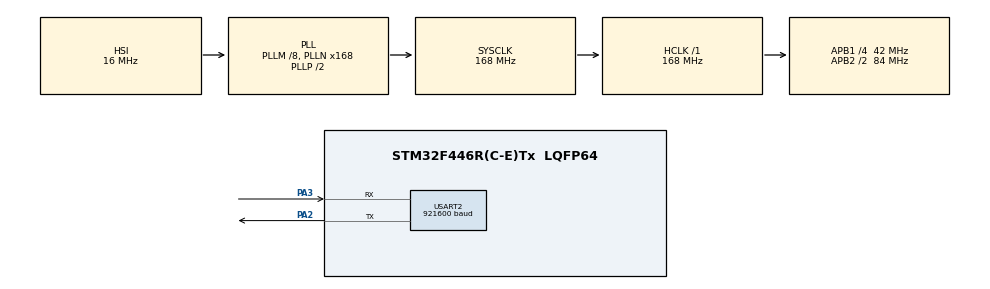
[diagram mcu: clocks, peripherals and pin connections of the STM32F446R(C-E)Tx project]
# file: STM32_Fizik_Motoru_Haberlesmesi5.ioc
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Dma.Request0=USART2_RX
Dma.USART2_RX.0.Direction=DMA_PERIPH_TO_MEMORY
Dma.USART2_RX.0.FIFOMode=DMA_FIFOMODE_DISABLE
Dma.USART2_RX.0.Instance=DMA1_Stream5
Dma.USART2_RX.0.MemDataAlignment=DMA_MDATAALIGN_BYTE
Dma.USART2_RX.0.MemInc=DMA_MINC_ENABLE
Dma.USART2_RX.0.Mode=DMA_NORMAL
Dma.USART2_RX.0.PeriphDataAlignment=DMA_PDATAALIGN_BYTE
Dma.USART2_RX.0.PeriphInc=DMA_PINC_DISABLE
Dma.USART2_RX.0.Priority=DMA_PRIORITY_HIGH
Mcu.Family=STM32F4
Mcu.Name=STM32F446R(C-E)Tx
Mcu.Package=LQFP64
NVIC.DMA1_Stream5_IRQn=true\:0\:0\:false\:false\:true\:false\:true\:true
NVIC.PriorityGroup=NVIC_PRIORITYGROUP_4
NVIC.TIM3_IRQn=true\:0\:0\:false\:false\:true\:true\:true\:true
NVIC.USART2_IRQn=true\:0\:0\:false\:false\:true\:true\:true\:true
PA2.Mode=Asynchronous
PA2.Signal=USART2_TX
PA3.Mode=Asynchronous
PA3.Signal=USART2_RX
ProjectManager.HeapSize=0x200
ProjectManager.StackSize=0x400
ProjectManager.TargetToolchain=STM32CubeIDE
RCC.AHBFreq_Value=168000000
RCC.APB1CLKDivider=RCC_HCLK_DIV4
RCC.APB1Freq_Value=42000000
RCC.APB1TimFreq_Value=84000000
RCC.APB2CLKDivider=RCC_HCLK_DIV2
RCC.APB2Freq_Value=84000000
RCC.APB2TimFreq_Value=168000000
RCC.CortexFreq_Value=168000000
RCC.HCLKFreq_Value=168000000
RCC.PLLM=8
RCC.PLLN=168
RCC.SYSCLKFreq_VALUE=168000000
RCC.SYSCLKSource=RCC_SYSCLKSOURCE_PLLCLK
RCC.USBFreq_Value=168000000
RCC.VCOOutputFreq_Value=336000000
TIM3.AutoReloadPreload=TIM_AUTORELOAD_PRELOAD_ENABLE
TIM3.Period=4999
TIM3.Prescaler=84
USART2.BaudRate=921600
USART2.VirtualMode=VM_ASYNC
VP_TIM3_VS_ClockSourceINT.Mode=Internal
board=custom

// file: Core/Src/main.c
/* USER CODE BEGIN Header */
/**
  ******************************************************************************
  * @file           : main.c
  * @brief          : Main program body
  ******************************************************************************
  * @attention
  *
  * Copyright (c) 2026 STMicroelectronics.
  * All rights reserved.
  *
  * This software is licensed under terms that can be found in the LICENSE file
  * in the root directory of this software component.
  * If no LICENSE file comes with this software, it is provided AS-IS.
  *
  ******************************************************************************
  */
/* USER CODE END Header */
#include "main.h"

/* USER CODE BEGIN Includes */
#include "fm_haberlesme.h"
#include "fm_sistem.h"

//MODEL UYDU TEKNOFEST 2026 FİZİK MOTORU İLE SİMÜLASYON KODU 5

//Godotta yazılan fizik motorundan veri gelmedikçe sistem zamanı ilerlemeyecek.
//Stm32den de fizik motoruna veri gitmedikçe fizik motorunda zaman ilerlemeyecek
//(Ping pong Senkron Yapısı)

/* USER CODE END Includes */

TIM_HandleTypeDef htim3;

UART_HandleTypeDef huart2;
DMA_HandleTypeDef hdma_usart2_rx;

void SystemClock_Config(void);
static void MX_GPIO_Init(void);
static void MX_DMA_Init(void);
static void MX_USART2_UART_Init(void);
static void MX_TIM3_Init(void);

int main(void)
{

  /* MCU Configuration--------------------------------------------------------*/

  /* Reset of all peripherals, Initializes the Flash interface and the Systick. */
  HAL_Init();

  /* Configure the system clock */
  SystemClock_Config();

  /* Initialize all configured peripherals */
  MX_GPIO_Init();
  MX_DMA_Init();
  MX_USART2_UART_Init();
  MX_TIM3_Init();
  /* USER CODE BEGIN 2 */

  // 1. Kütüphaneye donanımları tanıtıyoruz (USART2 ve TIM3 senin yapılandırmana göre)
  Donanim_Sec(&huart2, &htim3);

  // 2. Tamponlarımızı oluşturuyoruz
  Alim_Veri_t   gelen_paket;
  Iletim_Veri_t gidecek_paket;
  memset(gidecek_paket.buffer, 0, sizeof(Iletim_Paketi_t));
  memset(gelen_paket.buffer, 0, sizeof(Alim_Paketi_t));
  /* USER CODE END 2 */

  /* Infinite loop */
  while (1)
  {

    /* USER CODE BEGIN 3 */

	// --- 1. Alım Paketini Al ---
	Paket_Durum_t alim_durumu = Alim_Paketini_Al(&gelen_paket);

	// --- 2. KONTROL 1: Bozuk Paket Mi? ---
	// (Paket eksik geldiyse VEYA Header/Checksum uyuşmazlığı varsa)
	if (alim_durumu == PAKET_EKSIK || Bozuk_Paket_Mi(&gelen_paket) != 0)
	{
		// Sabit Alarm Paketini Gönder ve döngüyü başa sar (Ok yukarı döner)
		Gonder((Iletim_Veri_t*)&ALARM_PAKETI_SABIT);
		continue;
	}

	// --- 3. KONTROL 2: Alarm Paket Mi? ---
	// (Fizik motoru bizden son paketi tekrar istiyorsa)
	if (Alarm_Paket_Mi(&gelen_paket) == 1)
	{
		// En Son Paketi Bir Daha Oluştur, Gönder ve döngüyü başa sar
		En_Son_Paketi_Bir_Daha_Olustur(&gidecek_paket);
		Gonder(&gidecek_paket);
		continue;
	}

	// --- 4. Sistem Davranışını Uygula ---
	// (Hiçbir hata yok, gelen temiz veriyi işleyip motor itkilerini belirle)
	Sistem_Davranisini_Hesapla(&gelen_paket, &gidecek_paket);

	// --- 5. İletim Paketini Oluştur ---
	// (Checksum hesapla ve paketi statik yedeğe mühürle)
	Iletim_Paketini_Olustur(&gidecek_paket);

	// --- 6. GÖNDER ---
	Gonder(&gidecek_paket);

  }
  /* USER CODE END 3 */
}

void SystemClock_Config(void)
{
  RCC_OscInitTypeDef RCC_OscInitStruct = {0};
  RCC_ClkInitTypeDef RCC_ClkInitStruct = {0};

  /** Configure the main internal regulator output voltage
  */
  __HAL_RCC_PWR_CLK_ENABLE();
  __HAL_PWR_VOLTAGESCALING_CONFIG(PWR_REGULATOR_VOLTAGE_SCALE1);

  /** Initializes the RCC Oscillators according to the specified parameters
  * in the RCC_OscInitTypeDef structure.
  */
  RCC_OscInitStruct.OscillatorType = RCC_OSCILLATORTYPE_HSI;
  RCC_OscInitStruct.HSIState = RCC_HSI_ON;
  RCC_OscInitStruct.HSICalibrationValue = RCC_HSICALIBRATION_DEFAULT;
  RCC_OscInitStruct.PLL.PLLState = RCC_PLL_ON;
  RCC_OscInitStruct.PLL.PLLSource = RCC_PLLSOURCE_HSI;
  RCC_OscInitStruct.PLL.PLLM = 8;
  RCC_OscInitStruct.PLL.PLLN = 168;
  RCC_OscInitStruct.PLL.PLLP = RCC_PLLP_DIV2;
  RCC_OscInitStruct.PLL.PLLQ = 2;
  RCC_OscInitStruct.PLL.PLLR = 2;
  if (HAL_RCC_OscConfig(&RCC_OscInitStruct) != HAL_OK)
  {
    Error_Handler();
  }

  /** Initializes the CPU, AHB and APB buses clocks
  */
  RCC_ClkInitStruct.ClockType = RCC_CLOCKTYPE_HCLK|RCC_CLOCKTYPE_SYSCLK
                              |RCC_CLOCKTYPE_PCLK1|RCC_CLOCKTYPE_PCLK2;
  RCC_ClkInitStruct.SYSCLKSource = RCC_SYSCLKSOURCE_PLLCLK;
  RCC_ClkInitStruct.AHBCLKDivider = RCC_SYSCLK_DIV1;
  RCC_ClkInitStruct.APB1CLKDivider = RCC_HCLK_DIV4;
  RCC_ClkInitStruct.APB2CLKDivider = RCC_HCLK_DIV2;

  if (HAL_RCC_ClockConfig(&RCC_ClkInitStruct, FLASH_LATENCY_5) != HAL_OK)
  {
    Error_Handler();
  }
}

static void MX_TIM3_Init(void)
{

  TIM_ClockConfigTypeDef sClockSourceConfig = {0};
  TIM_MasterConfigTypeDef sMasterConfig = {0};

  htim3.Instance = TIM3;
  htim3.Init.Prescaler = 84;
  htim3.Init.CounterMode = TIM_COUNTERMODE_UP;
  htim3.Init.Period = 4999;
  htim3.Init.ClockDivision = TIM_CLOCKDIVISION_DIV1;
  htim3.Init.AutoReloadPreload = TIM_AUTORELOAD_PRELOAD_ENABLE;
  if (HAL_TIM_Base_Init(&htim3) != HAL_OK)
  {
    Error_Handler();
  }
  sClockSourceConfig.ClockSource = TIM_CLOCKSOURCE_INTERNAL;
  if (HAL_TIM_ConfigClockSource(&htim3, &sClockSourceConfig) != HAL_OK)
  {
    Error_Handler();
  }
  sMasterConfig.MasterOutputTrigger = TIM_TRGO_RESET;
  sMasterConfig.MasterSlaveMode = TIM_MASTERSLAVEMODE_DISABLE;
  if (HAL_TIMEx_MasterConfigSynchronization(&htim3, &sMasterConfig) != HAL_OK)
  {
    Error_Handler();
  }

}

static void MX_USART2_UART_Init(void)
{

  huart2.Instance = USART2;
  huart2.Init.BaudRate = 921600;
  huart2.Init.WordLength = UART_WORDLENGTH_8B;
  huart2.Init.StopBits = UART_STOPBITS_1;
  huart2.Init.Parity = UART_PARITY_NONE;
  huart2.Init.Mode = UART_MODE_TX_RX;
  huart2.Init.HwFlowCtl = UART_HWCONTROL_NONE;
  huart2.Init.OverSampling = UART_OVERSAMPLING_16;
  if (HAL_UART_Init(&huart2) != HAL_OK)
  {
    Error_Handler();
  }

}

static void MX_DMA_Init(void)
{

  /* DMA controller clock enable */
  __HAL_RCC_DMA1_CLK_ENABLE();

  /* DMA interrupt init */
  /* DMA1_Stream5_IRQn interrupt configuration */
  HAL_NVIC_SetPriority(DMA1_Stream5_IRQn, 0, 0);
  HAL_NVIC_EnableIRQ(DMA1_Stream5_IRQn);

}

static void MX_GPIO_Init(void)
{

  /* GPIO Ports Clock Enable */
  __HAL_RCC_GPIOA_CLK_ENABLE();

}

void Error_Handler(void)
{
  __disable_irq();
  while (1)
  {
  }
}
